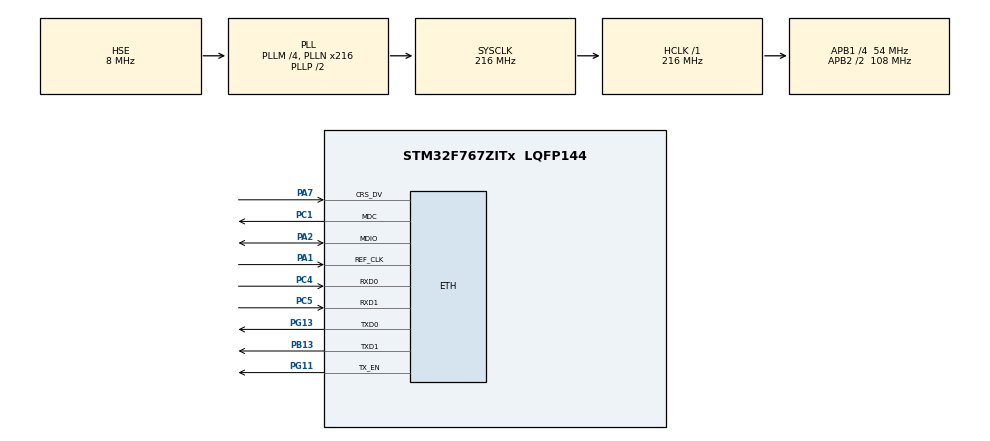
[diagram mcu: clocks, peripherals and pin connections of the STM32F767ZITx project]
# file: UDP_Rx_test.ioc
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CORTEX_M7.AccessPermission-Cortex_Memory_Protection_Unit_Region0_Settings=MPU_REGION_FULL_ACCESS
CORTEX_M7.BaseAddress-Cortex_Memory_Protection_Unit_Region0_Settings=0x20010000
CORTEX_M7.CPU_DCache=Enabled
CORTEX_M7.CPU_ICache=Enabled
CORTEX_M7.DisableExec-Cortex_Memory_Protection_Unit_Region0_Settings=MPU_INSTRUCTION_ACCESS_DISABLE
CORTEX_M7.Enable-Cortex_Memory_Protection_Unit_Region0_Settings=MPU_REGION_ENABLE
CORTEX_M7.IsShareable-Cortex_Memory_Protection_Unit_Region0_Settings=MPU_ACCESS_SHAREABLE
CORTEX_M7.MPU_Control=__NULL
CORTEX_M7.PREFETCH_ENABLE=1
CORTEX_M7.Size-Cortex_Memory_Protection_Unit_Region0_Settings=MPU_REGION_SIZE_16KB
CORTEX_M7.TypeExtField-Cortex_Memory_Protection_Unit_Region0_Settings=MPU_TEX_LEVEL1
ETH.MediaInterface=HAL_ETH_RMII_MODE
LWIP.BSP.number=1
LWIP.IP_ADDRESS=192.168.000.111
LWIP.LWIP_DHCP=0
LWIP.LWIP_IPV6=0
LWIP.MEM_SIZE=10*1024
LWIP.NETMASK_ADDRESS=255.255.255.000
LWIP.Version=v2.1.2_Cube
LWIP0.BSP.STBoard=false
LWIP0.BSP.api=BSP_COMPONENT_DRIVER
LWIP0.BSP.component=LAN8742
LWIP0.BSP.instance=LAN8742
LWIP0.BSP.name=Driver_PHY
LWIP0.BSP.semaphore=S_LAN8742
LWIP0.BSP.solution=LAN8742
Mcu.Family=STM32F7
Mcu.Name=STM32F767ZITx
Mcu.Package=LQFP144
NVIC.ETH_IRQn=true\:0\:0\:false\:false\:true\:true\:true\:true
NVIC.PriorityGroup=NVIC_PRIORITYGROUP_4
PA1.Mode=RMII
PA1.Signal=ETH_REF_CLK
PA2.Mode=RMII
PA2.Signal=ETH_MDIO
PA7.Mode=RMII
PA7.Signal=ETH_CRS_DV
PB13.Mode=RMII
PB13.Signal=ETH_TXD1
PC1.Mode=RMII
PC1.Signal=ETH_MDC
PC4.Mode=RMII
PC4.Signal=ETH_RXD0
PC5.Mode=RMII
PC5.Signal=ETH_RXD1
PG11.Mode=RMII
PG11.Signal=ETH_TX_EN
PG13.Mode=RMII
PG13.Signal=ETH_TXD0
PH0/OSC_IN.Mode=HSE-External-Clock-Source
PH0/OSC_IN.Signal=RCC_OSC_IN
PH1/OSC_OUT.Mode=HSE-External-Clock-Source
PH1/OSC_OUT.Signal=RCC_OSC_OUT
ProjectManager.HeapSize=0x200
ProjectManager.StackSize=0x400
ProjectManager.TargetToolchain=STM32CubeIDE
RCC.48MHZClocksFreq_Value=24000000
RCC.AHBFreq_Value=216000000
RCC.APB1CLKDivider=RCC_HCLK_DIV4
RCC.APB1Freq_Value=54000000
RCC.APB1TimFreq_Value=108000000
RCC.APB2CLKDivider=RCC_HCLK_DIV2
RCC.APB2Freq_Value=108000000
RCC.APB2TimFreq_Value=216000000
RCC.CortexFreq_Value=216000000
RCC.HCLKFreq_Value=216000000
RCC.HSE_VALUE=8000000
RCC.HSI_VALUE=16000000
RCC.LSE_VALUE=32768
RCC.PLLM=4
RCC.PLLMUL=RCC_PLL_MUL9
RCC.PLLN=216
RCC.PLLQ=4
RCC.PLLSourceVirtual=RCC_PLLSOURCE_HSE
RCC.PRESCALERUSB=RCC_USBCLKSOURCE_PLL_DIV1_5
RCC.SYSCLKFreq_VALUE=216000000
RCC.SYSCLKSource=RCC_SYSCLKSOURCE_PLLCLK
RCC.SYSCLKSourceVirtual=RCC_SYSCLKSOURCE_PLLCLK
RCC.USBFreq_Value=108000000
RCC.VCOOutputFreq_Value=432000000
VP_LWIP_VS_Enabled.Mode=Enabled
board=NUCLEO-F767ZI

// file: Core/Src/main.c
/* USER CODE BEGIN Header */
/**
  ******************************************************************************
  * @file           : main.c
  * @brief          : Main program body
  ******************************************************************************
  * @attention
  *
  * Copyright (c) 2026 STMicroelectronics.
  * All rights reserved.
  *
  * This software is licensed under terms that can be found in the LICENSE file
  * in the root directory of this software component.
  * If no LICENSE file comes with this software, it is provided AS-IS.
  *
  ******************************************************************************
  */
/* USER CODE END Header */
#include "main.h"
#include "lwip.h"

/* USER CODE BEGIN Includes */
#include <string.h>
#include <stdint.h>
//#include "app_udp.h"

/* USER CODE END Includes */

void SystemClock_Config(void);
static void MX_GPIO_Init(void);
/* USER CODE BEGIN PFP */

extern struct netif_default gnetif;
//typedef struct {
//  double jd;
//  double x, y, z;
//  double vx, vy, vz;
//  double q0, q1, q2, q3;
//  double wx, wy, wz;
//  double mode;  // ส่งมาเป็น double แต่ถือค่า int
//} pkt15d_t;
//
//uint8_t rx[256];
//uint16_t rx_len = 0;
//pkt15d_t st;
//
//// คืนค่า 1 ถ้า parse ได้, 0 ถ้าไม่ได้
//static int parse_pkt15d(const uint8_t *buf, uint16_t len, pkt15d_t *out)
//{
//  const uint8_t *p = buf;
//  uint16_t n = len;
//
//  // รองรับ header "BSK2"
//  if (n == (4U + 15U*8U) && memcmp(p, "BSK2", 4) == 0) {
//    p += 4;
//    n -= 4;
//  }
//
//  if (n != (15U*8U)) return 0;
//
//  // ระวัง alignment: memcpy ทีละ 8 bytes
//  double v[15];
//  for (int i = 0; i < 15; i++) {
//    memcpy(&v[i], p + (uint32_t)i*8U, 8U);
//  }
//
//  out->jd   = v[0];
//  out->x    = v[1];
//  out->y    = v[2];
//  out->z    = v[3];
//  out->vx   = v[4];
//  out->vy   = v[5];
//  out->vz   = v[6];
//  out->q0   = v[7];
//  out->q1   = v[8];
//  out->q2   = v[9];
//  out->q3   = v[10];
//  out->wx   = v[11];
//  out->wy   = v[12];
//  out->wz   = v[13];
//  out->mode = v[14];
//  return 1;
//}
/* USER CODE END PFP */

int main(void)
{

  /* Enable the CPU Cache */

  /* Enable I-Cache---------------------------------------------------------*/
  SCB_EnableICache();

  /* Enable D-Cache---------------------------------------------------------*/
  SCB_EnableDCache();

  /* MCU Configuration--------------------------------------------------------*/

  /* Reset of all peripherals, Initializes the Flash interface and the Systick. */
  HAL_Init();

  /* Configure the system clock */
  SystemClock_Config();

  /* Initialize all configured peripherals */
  MX_GPIO_Init();
  MX_LWIP_Init();
  /* USER CODE BEGIN 2 */
//  UDP_Server_Init(5000);

  /* USER CODE END 2 */

  /* Infinite loop */
  while (1)
  {

    /* USER CODE BEGIN 3 */
//	  MX_LWIP_Process();
//	  if (UDP_Server_Pop(rx, sizeof(rx), &rx_len)) {
//	    if (parse_pkt15d(rx, rx_len, &st)) {
//
//
//
//	    }
//	  }

	  ethernetif_input(&gnetif);
	      sys_check_timeouts();
  }
  /* USER CODE END 3 */
}

void SystemClock_Config(void)
{
  RCC_OscInitTypeDef RCC_OscInitStruct = {0};
  RCC_ClkInitTypeDef RCC_ClkInitStruct = {0};

  /** Configure the main internal regulator output voltage
  */
  __HAL_RCC_PWR_CLK_ENABLE();
  __HAL_PWR_VOLTAGESCALING_CONFIG(PWR_REGULATOR_VOLTAGE_SCALE1);

  /** Initializes the RCC Oscillators according to the specified parameters
  * in the RCC_OscInitTypeDef structure.
  */
  RCC_OscInitStruct.OscillatorType = RCC_OSCILLATORTYPE_HSE;
  RCC_OscInitStruct.HSEState = RCC_HSE_BYPASS;
  RCC_OscInitStruct.PLL.PLLState = RCC_PLL_ON;
  RCC_OscInitStruct.PLL.PLLSource = RCC_PLLSOURCE_HSE;
  RCC_OscInitStruct.PLL.PLLM = 4;
  RCC_OscInitStruct.PLL.PLLN = 216;
  RCC_OscInitStruct.PLL.PLLP = RCC_PLLP_DIV2;
  RCC_OscInitStruct.PLL.PLLQ = 4;
  RCC_OscInitStruct.PLL.PLLR = 2;
  if (HAL_RCC_OscConfig(&RCC_OscInitStruct) != HAL_OK)
  {
    Error_Handler();
  }

  /** Activate the Over-Drive mode
  */
  if (HAL_PWREx_EnableOverDrive() != HAL_OK)
  {
    Error_Handler();
  }

  /** Initializes the CPU, AHB and APB buses clocks
  */
  RCC_ClkInitStruct.ClockType = RCC_CLOCKTYPE_HCLK|RCC_CLOCKTYPE_SYSCLK
                              |RCC_CLOCKTYPE_PCLK1|RCC_CLOCKTYPE_PCLK2;
  RCC_ClkInitStruct.SYSCLKSource = RCC_SYSCLKSOURCE_PLLCLK;
  RCC_ClkInitStruct.AHBCLKDivider = RCC_SYSCLK_DIV1;
  RCC_ClkInitStruct.APB1CLKDivider = RCC_HCLK_DIV4;
  RCC_ClkInitStruct.APB2CLKDivider = RCC_HCLK_DIV2;

  if (HAL_RCC_ClockConfig(&RCC_ClkInitStruct, FLASH_LATENCY_7) != HAL_OK)
  {
    Error_Handler();
  }
}

static void MX_GPIO_Init(void)
{

  /* GPIO Ports Clock Enable */
  __HAL_RCC_GPIOH_CLK_ENABLE();
  __HAL_RCC_GPIOC_CLK_ENABLE();
  __HAL_RCC_GPIOA_CLK_ENABLE();
  __HAL_RCC_GPIOB_CLK_ENABLE();
  __HAL_RCC_GPIOG_CLK_ENABLE();

}

void Error_Handler(void)
{
  __disable_irq();
  while (1)
  {
  }
}
